# RL7005_IP_SVD register map
Vendor: Realtek
Registers are 32-bit, read-write, reset 0x0 unless marked. A register's access mark holds for its fields unless they carry their own. Offsets are from the block's base; [hi:lo] are bit positions; {n}, {i} and the like mark numbered series; <NAME> marks a mode.

## PAGE5 (part 1 of 2)
Base 0x40000000
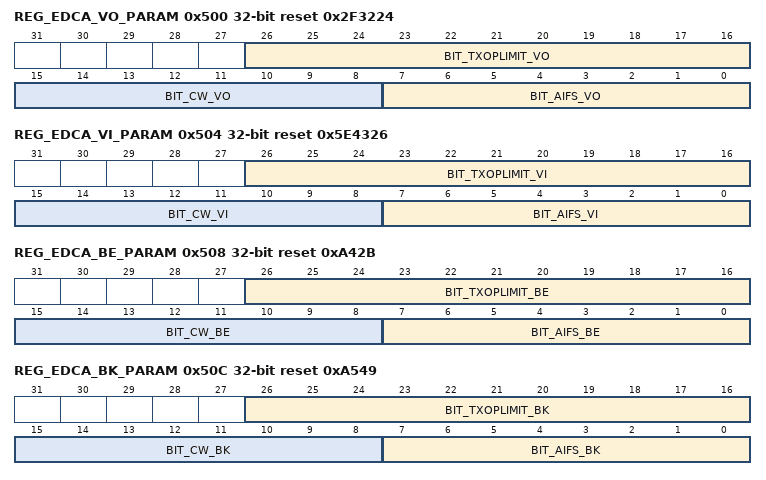
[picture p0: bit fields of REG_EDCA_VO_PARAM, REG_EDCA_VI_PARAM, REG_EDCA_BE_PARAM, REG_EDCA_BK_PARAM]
0x500 REG_EDCA_VO_PARAM reset 0x2F3224
  [26:16] BIT_TXOPLIMIT_VO — TXOP Limit An unsigned integer in units of 32 microseconds. Value of zero indicates that a single MSDU or MMPDU in addition to a protection frame exchange can be transmitted at any rate. Default: BK = 0h; BE = 0h; VI = 5Eh; VO = 2Fh.
  [15:8] BIT_CW_VO — ECWmin and ECWmax encode the values of Cwmin and Cwmax respectively in an exponent form. Ex: Cwmax = 2^(ECWmax)-1 Default: BK = Ah/5h; BE = Ah/5h; VI = 5h/4h; VO = 4h/3h.
  [7:0] BIT_AIFS_VO — Arbitrary Inter frame space In unit of microsecond. AIFS indicates the time a non-AP QSTA should defer before either invoking a backoff or starting a transmission Default: BK = 49h; BE = 25h; VI = 1Ch; VO = 1Ch.
0x504 REG_EDCA_VI_PARAM reset 0x5E4326
  [26:16] BIT_TXOPLIMIT_VI — TXOP Limit An unsigned integer in units of 32 microseconds. Value of zero indicates that a single MSDU or MMPDU in addition to a protection frame exchange can be transmitted at any rate. Default: BK = 0h; BE = 0h; VI = 5Eh; VO = 2Fh.
  [15:8] BIT_CW_VI — ECWmin and ECWmax encode the values of Cwmin and Cwmax respectively in an exponent form. Ex: Cwmax = 2^(ECWmax)-1 Default: BK = Ah/5h; BE = Ah/5h; VI = 5h/4h; VO = 4h/3h.
  [7:0] BIT_AIFS_VI — Arbitrary Inter frame space In unit of microsecond. AIFS indicates the time a non-AP QSTA should defer before either invoking a backoff or starting a transmission Default: BK = 49h; BE = 25h; VI = 1Ch; VO = 1Ch.
0x508 REG_EDCA_BE_PARAM reset 0xA42B
  [26:16] BIT_TXOPLIMIT_BE — TXOP Limit An unsigned integer in units of 32 microseconds. Value of zero indicates that a single MSDU or MMPDU in addition to a protection frame exchange can be transmitted at any rate. Default: BK = 0h; BE = 0h; VI = 5Eh; VO = 2Fh.
  [15:8] BIT_CW_BE — ECWmin and ECWmax encode the values of Cwmin and Cwmax respectively in an exponent form. Ex: Cwmax = 2^(ECWmax)-1 Default: BK = Ah/5h; BE = Ah/5h; VI = 5h/4h; VO = 4h/3h.
  [7:0] BIT_AIFS_BE — Arbitrary Inter frame space In unit of microsecond. AIFS indicates the time a non-AP QSTA should defer before either invoking a backoff or starting a transmission Default: BK = 49h; BE = 25h; VI = 1Ch; VO = 1Ch.
0x50C REG_EDCA_BK_PARAM reset 0xA549
  [26:16] BIT_TXOPLIMIT_BK — TXOP Limit An unsigned integer in units of 32 microseconds. Value of zero indicates that a single MSDU or MMPDU in addition to a protection frame exchange can be transmitted at any rate. Default: BK = 0h; BE = 0h; VI = 5Eh; VO = 2Fh.
  [15:8] BIT_CW_BK — ECWmin and ECWmax encode the values of Cwmin and Cwmax respectively in an exponent form. Ex: Cwmax = 2^(ECWmax)-1 Default: BK = Ah/5h; BE = Ah/5h; VI = 5h/4h; VO = 4h/3h.
  [7:0] BIT_AIFS_BK — Arbitrary Inter frame space In unit of microsecond. AIFS indicates the time a non-AP QSTA should defer before either invoking a backoff or starting a transmission Default: BK = 49h; BE = 25h; VI = 1Ch; VO = 1Ch.
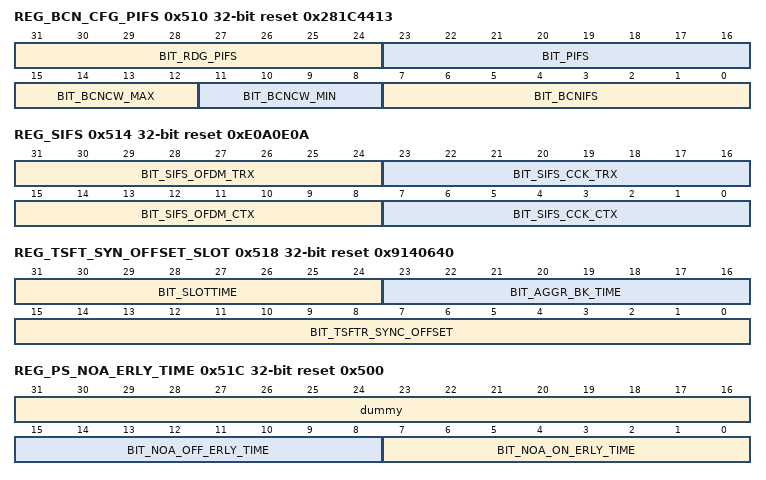
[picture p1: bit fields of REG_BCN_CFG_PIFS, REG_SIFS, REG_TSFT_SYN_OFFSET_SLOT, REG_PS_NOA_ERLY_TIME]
0x510 REG_BCN_CFG_PIFS reset 0x281C4413
  [31:24] BIT_RDG_PIFS — PIFS time. It is only used in RDG mode and in units of us.
  [23:16] BIT_PIFS — PIFS time. It is only used in AP mode and in units of us.
  [15:12] BIT_BCNCW_MAX — Beacon Contention Window MAX Defines the contention window value for back off before transmitting beacon frame. This field is set to 0 in AP mode to indicate no back off window. In ad hoc mode, its default value is 6. 26-1 = 63 time slots.
  [11:8] BIT_BCNCW_MIN — Beacon Contention Window Defines the contention window value for back off before transmitting beacon frame. This field is set to 0 in AP mode to indicate no back off window. In ad hoc mode, its default value is 6. 26-1 = 63 time slots.
  [7:0] BIT_BCNIFS — Beacon Interframe Space In units of microseconds, this register defines the medium idle time required before transmitting beacon (AP mode) or entering random back off window.
0x514 REG_SIFS reset 0xE0A0E0A
  [31:24] BIT_SIFS_OFDM_TRX — This register sets the SIFS time required in NAV protection period after receiving any immediate response. for example Ack-Data or RTS/CTS-Data. It is in unit of us.
  [23:16] BIT_SIFS_CCK_TRX — This register sets the SIFS time required in NAV protection period after receiving any immediate response. for example Ack-Data or RTS/CTS-Data. It is in unit of us.
  [15:8] BIT_SIFS_OFDM_CTX — This register sets the SIFS time required for consecutive TX events for example CTS2S-Data, or broadcast bursting. It is in unit of us.
  [7:0] BIT_SIFS_CCK_CTX — This register sets the SIFS time required for consecutive TX events for example CTS2S-Data, or broadcast bursting. It is in unit of us.
0x518 REG_TSFT_SYN_OFFSET_SLOT reset 0x9140640
  [31:24] BIT_SLOTTIME — This register sets the slot time value mentioned in 802.11 specification. It is in units of us. Default: 0x9
  [23:16] BIT_AGGR_BK_TIME — Hw will break aggr. In sifs condition
  [15:0] BIT_TSFTR_SYNC_OFFSET — tsft sync. Offset (bcn0 sync to bcn1 offset or bcn1 sync to bcn0 offset). Unit : 32us, default is 50ms
0x51C REG_PS_NOA_ERLY_TIME reset 0x500
  [31:16] dummy
  [15:8] BIT_NOA_OFF_ERLY_TIME — NOA off early interval, Time unit is TU.
  [7:0] BIT_NOA_ON_ERLY_TIME — not valid. NOA on early interval, Time unit is TU. PS: This function has some issue, so it's value must be 0
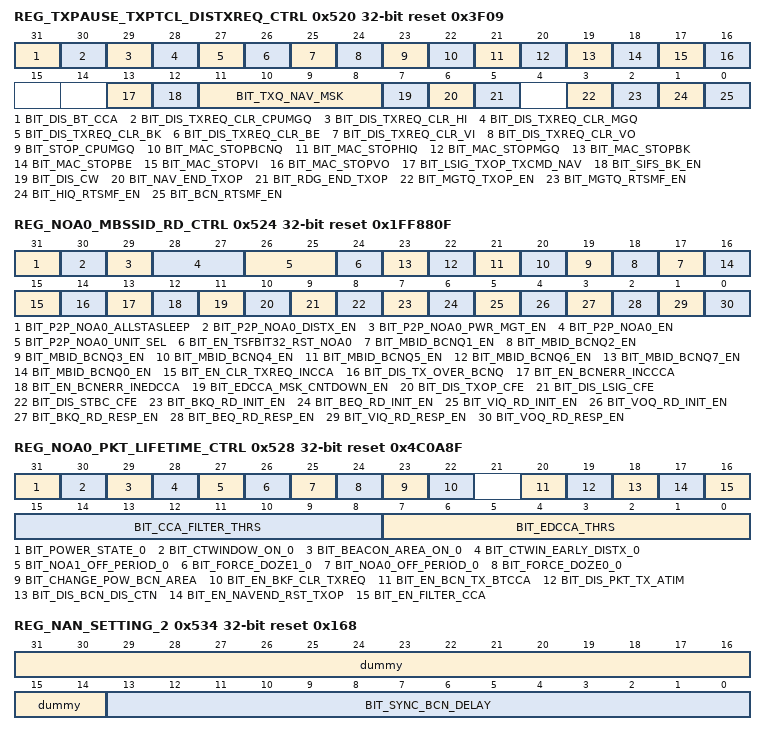
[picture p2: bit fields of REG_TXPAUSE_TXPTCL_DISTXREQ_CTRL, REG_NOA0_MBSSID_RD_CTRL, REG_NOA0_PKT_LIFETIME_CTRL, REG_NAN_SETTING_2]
0x520 REG_TXPAUSE_TXPTCL_DISTXREQ_CTRL reset 0x3F09
  [31] BIT_DIS_BT_CCA — Disable BT_CCA. (NOT USED, SEE 0x1594)
  [30] BIT_DIS_TXREQ_CLR_CPUMGQ — 1: if this queue can't own channel ,txcmd will be cleared 0:Only TX_finish can clear txreq
  [29] BIT_DIS_TXREQ_CLR_HI — 0: if this queue can't own channel ,txcmd will be cleared 1:Only TX_finish can clear txreq
  [28] BIT_DIS_TXREQ_CLR_MGQ — 1: if this queue can't own channel ,txcmd will be cleared 0:Only TX_finish can clear txreq
  [27] BIT_DIS_TXREQ_CLR_BK — 0: if this queue can't own channel ,txcmd will be cleared 1:Only TX_finish can clear txreq
  [26] BIT_DIS_TXREQ_CLR_BE — 0: if this queue can't own channel ,txcmd will be cleared 1:Only TX_finish can clear txreq
  [25] BIT_DIS_TXREQ_CLR_VI — 0: if this queue can't own channel ,txcmd will be cleared 1:Only TX_finish can clear txreq
  [24] BIT_DIS_TXREQ_CLR_VO — 0: if this queue can't own channel ,txcmd will be cleared 1:Only TX_finish can clear txreq
  [23] BIT_STOP_CPUMGQ — To control CPUMGQ queues contention circuit. 1: CPUMGQ queues all stop. 0: Enable CPUMGQ queues contention circuit
  [22] BIT_MAC_STOPBCNQ — Stop BCNQ Queue Write a 1 to this bit via software to immediately stop the transmission of packet from this queue including retry attempts.
  [21] BIT_MAC_STOPHIQ — Stop High Queue Write a 1 to this bit via software to immediately stop the transmission of packet from this queue including retry attempts.
  [20] BIT_MAC_STOPMGQ — Stop Management Queue Write a 1 to this bit via software to immediately stop the transmission of packet from this queue including retry attempts.
  [19] BIT_MAC_STOPBK — Stop BK Queue Write a 1 to this bit via software to immediately stop the transmission of packet from this queue including retry attempts.
  [18] BIT_MAC_STOPBE — Stop BE Queue Write a 1 to this bit via software to immediately stop the transmission of packet from this queue including retry attempts.
  [17] BIT_MAC_STOPVI — Stop VI Queue Write a 1 to this bit via software to immediately stop the transmission of packet from this queue including retry attempts.
  [16] BIT_MAC_STOPVO — Stop VO Queue Write a 1 to this bit via software to immediately stop the transmission of packet from this queue including retry attempts.
  [13] BIT_LSIG_TXOP_TXCMD_NAV — Set LSIG_TXOP from TXCMD_NAV field
  [12] BIT_SIFS_BK_EN — SIFS Break Check Criteria enable for AMPDU aggregation
  [11:8] BIT_TXQ_NAV_MSK — 1: Queue BKF must wait TX Nav finished 0: Queue not need wait
  [7] BIT_DIS_CW — When this bit is set, disable CW.
  [6] BIT_NAV_END_TXOP — 1: In txop mode, Nav protect all txop 0: In txop mode, Nav protect to next pkt
  [5] BIT_RDG_END_TXOP — 1: In tx RDG mode, Nav protect all txop 0: In tx RDG mode, Nav protect to next pkt
  [3] BIT_MGTQ_TXOP_EN — When this bit is set, MGTQ may sent packets by using ACQ TXOP.
  [2] BIT_MGTQ_RTSMF_EN — When this bit is set, MTGQ will be TX, not wait until RTS or MF transaction finished.
  [1] BIT_HIQ_RTSMF_EN — When this bit is set, HIQ will be TX, not wait until RTS or MF transaction finished.
  [0] BIT_BCN_RTSMF_EN — When this bit is set, BCNQ will be TX, not wait until RTS or MF transaction finished.
0x524 REG_NOA0_MBSSID_RD_CTRL reset 0x1FF880F
  [31] BIT_P2P_NOA0_ALLSTASLEEP — It indicates that the state from CTWindow End to BcnEarly 1: Sleep 0: Wake
  [30] BIT_P2P_NOA0_DISTX_EN — 1: Hw will disable TX in P2P_off period 0: Do Nothing
  [29] BIT_P2P_NOA0_PWR_MGT_EN — A main switch for P2P PowerSaving 1: Enable 0: Disable
  [28:27] BIT_P2P_NOA0_EN — The condition that noa_unit0, [1]-NOA1, [0]-NOA0 1: Enable 0: Disable
  [26:25] BIT_P2P_NOA0_UNIT_SEL — The selector for the source of noa unit0. 0 for port 0, 1 for port 1,2 for port2
  [24] BIT_EN_TSFBIT32_RST_NOA0 — when enable, if tsft_bit32_int is asserted, reset power_cs of noa_unit0
  [n+16] BIT_MBID_BCNQ{n}_EN (n=1..7) — When enable, auto MBSSID for virtual interface {n} is enable.
  [16] BIT_MBID_BCNQ0_EN — When enable, auto MBSSID for root interface is enable.
  [15] BIT_EN_CLR_TXREQ_INCCA — not valid.
  [14] BIT_DIS_TX_OVER_BCNQ — 1: Tx Packet with ignoring Beacon Area time 0: Disable
  [13] BIT_EN_BCNERR_INCCCA — eneble force tx becon ignore CCA in disable contention area
  [12] BIT_EN_BCNERR_INEDCCA — eneble force tx becon ignore EDCCA in disable contention area
  [11] BIT_EDCCA_MSK_CNTDOWN_EN — 1: disable EDCCA count down, 0: enable EDCCA count down AC backoff 是否需要參考PHY_EDCCA 0: 不參考PHY_EDCCA 1: 參考PHY_EDCCA (default, PHY_EDCCA=1時停止backoff)
  [10] BIT_DIS_TXOP_CFE — Disable TXOP_CFE function
  [9] BIT_DIS_LSIG_CFE — Disable LSIG_TXOP CF-END function
  [8] BIT_DIS_STBC_CFE — Disable STBC CF-END function
  [7] BIT_BKQ_RD_INIT_EN — Enable BKQ RD initiator function
  [6] BIT_BEQ_RD_INIT_EN — Enable BEQ RD initiator function
  [5] BIT_VIQ_RD_INIT_EN — Enable VIQ RD initiator function
  [4] BIT_VOQ_RD_INIT_EN — Enable VOQ RD initiator function
  [3] BIT_BKQ_RD_RESP_EN — Enable BKQ RD responder function
  [2] BIT_BEQ_RD_RESP_EN — Enable BEQ RD responder function
  [1] BIT_VIQ_RD_RESP_EN — Enable VIQ RD responder function
  [0] BIT_VOQ_RD_RESP_EN — Enable VOQ RD responder function
0x528 REG_NOA0_PKT_LIFETIME_CTRL access per field reset 0x4C0A8F
  [31] BIT_POWER_STATE_0 ro — 1: On, 0: Off. (It is including early time. )
  [30] BIT_CTWINDOW_ON_0 ro — Spec time and Beacon Early Time to TBTT Time. (It is including early time. )
  [29] BIT_BEACON_AREA_ON_0 ro — The time is from HOLD Time to BeaconTx or Timeout. (It is including early time. )
  [28] BIT_CTWIN_EARLY_DISTX_0 ro — ctwin_early_distx. (It is including early time. )
  [27] BIT_NOA1_OFF_PERIOD_0 ro — Spec time but exclude BCNDMATIM time for wake. (It is including early time. )
  [26] BIT_FORCE_DOZE1_0 ro — If NoA_Count == 1, this value is 1. else 0. (It is including early time. )
  [25] BIT_NOA0_OFF_PERIOD_0 ro — Spec time but exclude BCNDMATIM time for wake. (It is including early time. )
  [24] BIT_FORCE_DOZE0_0 ro — If NoA_Count == 1, this value is 1. else 0. (It is including early time. )
  [23] BIT_CHANGE_POW_BCN_AREA rw — select real_ctwindow & real_bcnq_area for noa_unit
  [22] BIT_EN_BKF_CLR_TXREQ rw — when gen tx command done, while will backoff is invalid, then tx command will be cleared
  [20] BIT_EN_BCN_TX_BTCCA rw — 1: Enable Beacon Tx at TBTT if BT_CCA is enabled 0: Disable
  [19] BIT_DIS_PKT_TX_ATIM rw — 1: Disable AC Queue Packet Tx in ATIM (only valid at Nettype: Adhoc/AP) 0: Enable AC Queue packet Tx in ATIM
  [18] BIT_DIS_BCN_DIS_CTN rw — Disable the Beacon queue disable contention,when set to 0 enable the force beacon function.
  [17] BIT_EN_NAVEND_RST_TXOP rw — When set this bit, TXOP will be reset while NAV end.
  [16] BIT_EN_FILTER_CCA rw — Enable CCA filter threshold
  [15:8] BIT_CCA_FILTER_THRS rw — If PHY_CCA signal width is bigger than this threshold, this PHY_CCA signal is valid for MAC. Unit: us
  [7:0] BIT_EDCCA_THRS rw — EDCCA threshold value, edcca over this threshold will cause bkf_rst Bit[7]: PHY_EDCCA為1時,當timer timeout時擋住TX Bit[6:0]: timer (單位:32us)
0x530 REG_P2PON_DIS_TXTIME
  [15:8] BIT_P2PON_DIS_TXTIME — The time of the disable TX period after the P2P RF on interrupt occur. Unit: 64us.
0x534 REG_NAN_SETTING_2 reset 0x168
  [31:14] dummy
  [13:0] BIT_SYNC_BCN_DELAY — r_HC * r_SLOTTIME * 8'd40 (unit:us) default: r_HC = 1, r_SLOTTIME = 9, => 360us max is 16ms (DW)
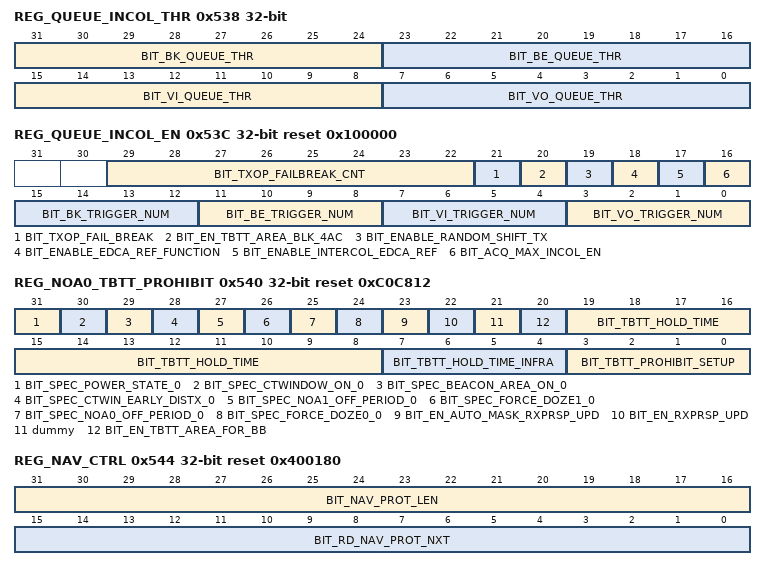
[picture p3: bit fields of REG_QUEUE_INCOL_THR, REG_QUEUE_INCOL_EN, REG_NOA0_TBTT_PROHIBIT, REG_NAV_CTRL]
0x538 REG_QUEUE_INCOL_THR
  [31:24] BIT_BK_QUEUE_THR — 0: Disable this BK queue condition. Otherwise: When internal collision number of queue equal threshold, the priority of queue enhance. But have more 2 queues which satisfy each queue threshold, the priority will follow VO>VI>BE>BK.
  [23:16] BIT_BE_QUEUE_THR — 0: Disable this BE queue condition. Otherwise: When internal collision number of queue equal threshold, the priority of queue enhance. But have more 2 queues which satisfy each queue threshold, the priority will follow VO>VI>BE>BK.
  [15:8] BIT_VI_QUEUE_THR — 0: Disable this VI queue condition. Otherwise: When internal collision number of queue equal threshold, the priority of queue enhance. But have more 2 queues which satisfy each queue threshold, the priority will follow VO>VI>BE>BK.
  [7:0] BIT_VO_QUEUE_THR — 0: Disable this VO queue condition. Otherwise: When internal collision number of queue equal threshold, the priority of queue enhance. But have more 2 queues which satisfy each queue threshold, the priority will follow VO>VI>BE>BK.
0x53C REG_QUEUE_INCOL_EN access per field reset 0x100000
  [29:22] BIT_TXOP_FAILBREAK_CNT ro — if BIT_TXOP_FAIL_BREAK = 1, counter the times of txfail break TXOP
  [21] BIT_TXOP_FAIL_BREAK rw — 1: if tx pkt fail in txop, then tx cfend to end txop
  [20] BIT_EN_TBTT_AREA_BLK_4AC rw — When set this bit, 4AC backoff is disabled on TBTT setup period
  [19] BIT_ENABLE_RANDOM_SHIFT_TX rw — When this bit set 1, enable random shift TX function
  [18] BIT_ENABLE_EDCA_REF_FUNCTION rw — When this bit set 1, enable EDCA REF function
  [17] BIT_ENABLE_INTERCOL_EDCA_REF rw — When this bit set 1, enable inter-collision edca_ref
  [16] BIT_ACQ_MAX_INCOL_EN rw — 1:Enable 0 :Disable
  [15:12] BIT_BK_TRIGGER_NUM ro — The number is triggered by bkq inter collision
  [11:8] BIT_BE_TRIGGER_NUM ro — The number is triggered by beq inter collision
  [7:4] BIT_VI_TRIGGER_NUM ro — The number is triggered by viq inter collision
  [3:0] BIT_VO_TRIGGER_NUM ro — The number is triggered by voq inter collision
0x540 REG_NOA0_TBTT_PROHIBIT access per field reset 0xC0C812
  [31] BIT_SPEC_POWER_STATE_0 ro — 1: On, 0: Off
  [30] BIT_SPEC_CTWINDOW_ON_0 ro — The time from TBTT <-> CTWEND (with BCNDMATIM early time)
  [29] BIT_SPEC_BEACON_AREA_ON_0 ro — The time is from TBTT to BeaconTx or Timeout
  [28] BIT_SPEC_CTWIN_EARLY_DISTX_0 ro — ctwin_early_distx
  [27] BIT_SPEC_NOA1_OFF_PERIOD_0 ro — Spec time
  [26] BIT_SPEC_FORCE_DOZE1_0 ro — If NoA_Count == 1, this value is 1. else 0.
  [25] BIT_SPEC_NOA0_OFF_PERIOD_0 ro — Spec time
  [24] BIT_SPEC_FORCE_DOZE0_0 ro — If NoA_Count == 1, this value is 1. else 0.
  [23] BIT_EN_AUTO_MASK_RXPRSP_UPD rw — valid when BIT_EN_RXPRSP_UPD = 1 1: auto disable RXPRSP's tsft update when rx probe response frame during bcn_early to tbtt
  [22] BIT_EN_RXPRSP_UPD rw — 1: enable update tsft when RX probe response frame
  [21] dummy rw
  [20] BIT_EN_TBTT_AREA_FOR_BB rw — enable notify bb that mac p0 is in tbtt area
  [19:8] BIT_TBTT_HOLD_TIME rw — TBTT_prohibit_hold time for AP mode, unit is 32 us
  [7:4] BIT_TBTT_HOLD_TIME_INFRA rw — TBTT_prohibit_hold time for infrastructure mode , unit is 2 ms
  [3:0] BIT_TBTT_PROHIBIT_SETUP rw — TBTT_prohibit_setup, unit is 32us
0x544 REG_NAV_CTRL reset 0x400180
  [31:16] BIT_NAV_PROT_LEN — In TXOP mode ,NAV setting which protects next packets
  [15:0] BIT_RD_NAV_PROT_NXT — In RDG mode ,NAV setting which protects next packets
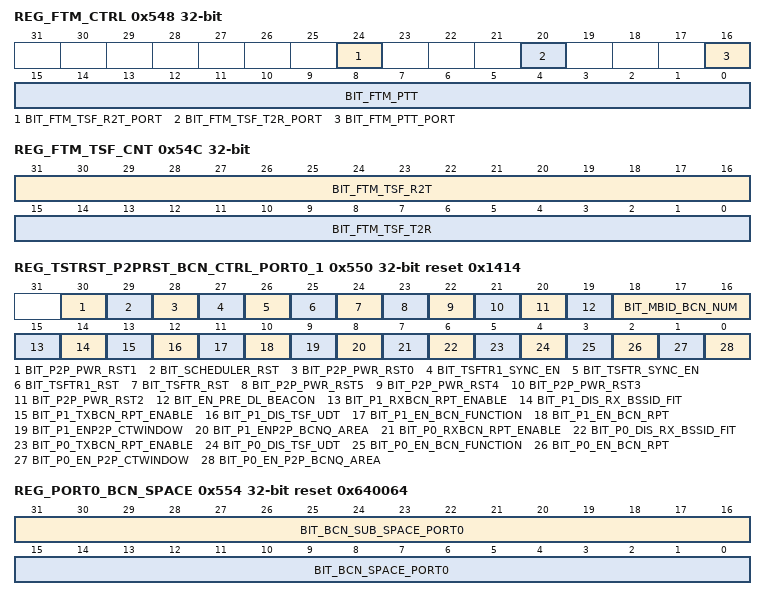
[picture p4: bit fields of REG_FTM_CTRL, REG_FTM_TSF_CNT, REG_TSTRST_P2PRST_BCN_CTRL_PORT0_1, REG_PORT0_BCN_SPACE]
0x548 REG_FTM_CTRL
  [24] BIT_FTM_TSF_R2T_PORT — 0:R2T latch count sync tsf of port 0 1: R2T latch count sync tsf of port 1
  [20] BIT_FTM_TSF_T2R_PORT — 0:T2R latch count sync tsf of port 0 1: T2R latch count sync tsf of port 1
  [16] BIT_FTM_PTT_PORT — 0: sync tsf of port 0 1: sync tsf of port 1
  [15:0] BIT_FTM_PTT — partial tsf timer setting
0x54C REG_FTM_TSF_CNT ro
  [31:16] BIT_FTM_TSF_R2T — R2T latch count sync tsf timer
  [15:0] BIT_FTM_TSF_T2R — T2R latch count sync tsf timer
0x550 REG_TSTRST_P2PRST_BCN_CTRL_PORT0_1 access per field reset 0x1414
  [30] BIT_P2P_PWR_RST1 wo — rst p2p circuit NOA 1, noa_unit0
  [29] BIT_SCHEDULER_RST wo — Write this bit reset scheduler, ioreg_txfail
  [28] BIT_P2P_PWR_RST0 wo — rst p2p circuit NOA 0, noa_unit0
  [27] BIT_TSFTR1_SYNC_EN wo — write this bit, bcn1 will sync to bcn0 with TSFTF_SYN_OFFSET
  [26] BIT_TSFTR_SYNC_EN wo — write this bit, bcn0 will sync to bcn1 with TSFTF_SYN_OFFSET
  [25] BIT_TSFTR1_RST wo — write this bit , bcn1 tsft will auto reset
  [24] BIT_TSFTR_RST wo — write this bit , bcn0 tsft will auto reset
  [23] BIT_P2P_PWR_RST5 wo — rst p2p circuit NOA 5, noa_unit2
  [22] BIT_P2P_PWR_RST4 wo — rst p2p circuit NOA 4, noa_unit2
  [21] BIT_P2P_PWR_RST3 wo — rst p2p circuit NOA 3, noa_unit1
  [20] BIT_P2P_PWR_RST2 wo — rst p2p circuit NOA 2, noa_unit1
  [19] BIT_EN_PRE_DL_BEACON rw — If set 1, hw will enable pre_download beacon
  [18:16] BIT_MBID_BCN_NUM rw — The number of virtual interface number excluding the root number.
  [15] BIT_P1_RXBCN_RPT_ENABLE rw — When this bit asserted, RXBCNOK report is issued
  [14] BIT_P1_DIS_RX_BSSID_FIT rw — 0:HW will handle rx_beacon 1:HW will ignore rx_beacon_pk
  [13] BIT_P1_TXBCN_RPT_ENABLE rw — When this bit and BIT_P1_EN_BCN_RPT are set, then TXBCN ERROR report is issued
  [12] BIT_P1_DIS_TSF_UDT rw — When set, disable clint 0 TSF update when beacon frames or probe response frames are received.
  [11] BIT_P1_EN_BCN_FUNCTION rw — When this bit is set, TSF and other beacon related functions are then enabled. 0x700(MACID1)的enable開關
  [10] BIT_P1_EN_BCN_RPT rw — When this bit asserted, txbcnok_int and txbcnerr_int will valid.
  [9] BIT_P1_ENP2P_CTWINDOW rw — 1: Enable P2P CTN WINDOWS function. 0: Disable P2P CTN WINDOWS function.
  [8] BIT_P1_ENP2P_BCNQ_AREA rw — 1: Enable P2P BCN area on function. 0 : Disable P2P BCN area on function.
  [7] BIT_P0_RXBCN_RPT_ENABLE rw — When this bit asserted, RXBCNOK report is issued
  [6] BIT_P0_DIS_RX_BSSID_FIT rw — 0:HW will handle rx_beacon 1:HW will ignore rx_beacon_pk
  [5] BIT_P0_TXBCN_RPT_ENABLE rw — When this bit and BIT_P0_EN_BCN_RPT are set, then TXBCN ERROR report is issued
  [4] BIT_P0_DIS_TSF_UDT rw — When set, disable port 0 TSF update when beacon frames or probe response frames are received.
  [3] BIT_P0_EN_BCN_FUNCTION rw — When this bit is set, TSF and other beacon related functions are then enabled. 0x610(MACID)的enable開關
  [2] BIT_P0_EN_BCN_RPT rw — When this bit asserted, txbcnok_int and txbcnerr_int will valid.
  [1] BIT_P0_EN_P2P_CTWINDOW rw — 1: Enable P2P CTN WINDOWS function. 0: Disable P2P CTN WINDOWS function.
  [0] BIT_P0_EN_P2P_BCNQ_AREA rw — 1: Enable P2P BCN area on function. 0 : Disable P2P BCN area on function.
0x554 REG_PORT0_BCN_SPACE reset 0x640064
  [31:16] BIT_BCN_SUB_SPACE_PORT0 — Unit is ms. The sub-beacon interval of the port 0.(valid if mbssid function is enable)
  [15:0] BIT_BCN_SPACE_PORT0 — Unit is ms. When MBSSID is disable, this field is the beacon interval. When MBSSID is enable, this register is the beacon space of root.
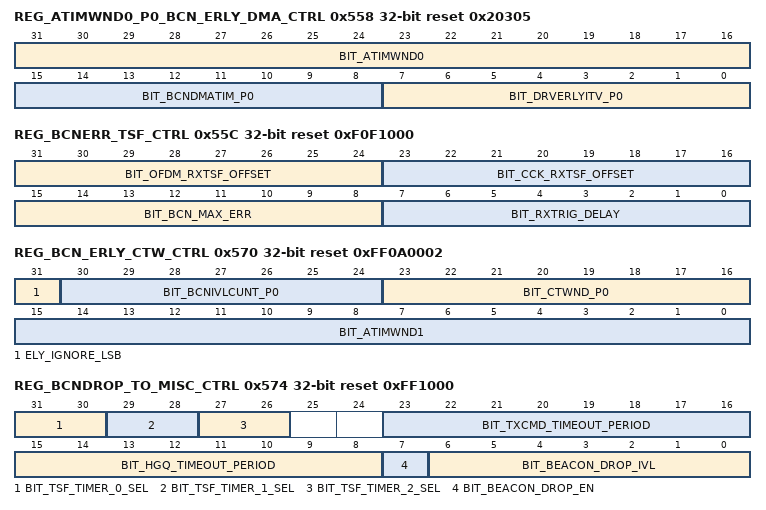
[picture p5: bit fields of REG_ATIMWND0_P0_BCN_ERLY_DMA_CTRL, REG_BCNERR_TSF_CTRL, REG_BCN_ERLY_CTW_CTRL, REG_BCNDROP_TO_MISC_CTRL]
0x558 REG_ATIMWND0_P0_BCN_ERLY_DMA_CTRL reset 0x20305
  [31:16] BIT_ATIMWND0 — ATIM window width of root VAP in units of TU.
  [15:8] BIT_BCNDMATIM_P0 — Indicates the time before TBTT to perform beacon queue DMA. This register is shared by the time to assert ATIM window end interrupt. Measured in units of "TU" before TBTT and before ATIM window end.
  [7:0] BIT_DRVERLYITV_P0 — Time to send interrupt to notify driver to change beacon content. Time unit is TU. The register also is shared by P2P-CTW and P2P-NoA (from NoA-Absent to NoA-On). It is used to wake up early at DriverEarlyTime
0x55C REG_BCNERR_TSF_CTRL reset 0xF0F1000
  [31:24] BIT_OFDM_RXTSF_OFFSET — The Datapath of OFDM RX_tsf
  [23:16] BIT_CCK_RXTSF_OFFSET — The Datapath of CCK RX_tsf
  [15:8] BIT_BCN_MAX_ERR — When beacon TX error counter goes over this threshold, Beacon will transmit within PIFS.
  [7:0] BIT_RXTRIG_DELAY — add compensation of RX trigger's TSFT. Unit: us
0x560 REG_P0_TSFTR_L reset 0x1
  [31:0] BIT_P0_TSF_TIMER_L — low 32bits of port0's tsft
0x564 REG_P0_TSFTR_H
  [31:0] BIT_P0_TSF_TIMER_H — high 32bits of port0's tsft
0x568 REG_P1_TSFTR_L reset 0x1
  [31:0] BIT_P1_TSF_TIMER_L — low 32bits of port1's tsft
0x56C REG_P1_TSFTR_H reset 0x1
  [31:0] BIT_P1_TSF_TIMER_H — high 32bits of port1's tsft
0x570 REG_BCN_ERLY_CTW_CTRL access per field reset 0xFF0A0002
  [31] ELY_IGNORE_LSB rw — 1:add1ms, add128us, add32us only check tsft[10], tsft[7], tsft[5], ignore LSB 0: add1ms, add128us, add32us check tsft[9:0], tsft[6:0], tsft[4:0] when active
  [30:24] BIT_BCNIVLCUNT_P0 ro — Be used in multiple BCNIVL early INT. When this counter =1, multiple BCNIVL early INT will be triggered.
  [23:16] BIT_CTWND_P0 rw — CTWindow width in units of TU. PORT0
  [15:0] BIT_ATIMWND1 rw — ATIM window width of VAP1 in units of TU.
0x574 REG_BCNDROP_TO_MISC_CTRL reset 0xFF1000
  [31:30] BIT_TSF_TIMER_0_SEL — genarete tsfime_int[0] 00: PORT0's tsft 01: PORT1's tsft 10:PORT2's tsft 11: FREERUN CUT
  [29:28] BIT_TSF_TIMER_1_SEL — genarete tsfime_int[1] 00: PORT0's tsft 01: PORT1's tsft 10:PORT2's tsft 11: FREERUN CUT
  [27:26] BIT_TSF_TIMER_2_SEL — genarete tsfime_int[2] 00: PORT0's tsft 01: PORT1's tsft 10:PORT2's tsft 11: FREERUN CUT
  [23:16] BIT_TXCMD_TIMEOUT_PERIOD — When 40M/80M TX CMD ready and secondary_CCA_20/secondary_CCA_40 set for this period, then the TX CMD will be cleared. TU: 1us
  [15:8] BIT_HGQ_TIMEOUT_PERIOD — When hgq empty for this period, close atim window. And this will block hgq dma for pcie, unless 0x524[12] set enable. TU: 32us
  [7] BIT_BEACON_DROP_EN — enable beacon drop function
  [6:0] BIT_BEACON_DROP_IVL — indicate the timeout of beacon drop
0x578 REG_P2_TSFTR_L ro reset 0x1
  [31:0] BIT_P2_TSF_TIMER_L — low 32bits of port2's tsft (NAN)
0x57C REG_P2_TSFTR_H ro reset 0x1
  [31:0] BIT_P2_TSF_TIMER_H — high 32bits of port2's tsft(NAN)
{0x57C+4i} REG_TSF_TIMER{i} (i=1..3)
  [31:5] BIT_TSTTIMER{i} — When the lower 4 bytes of TSFTR matches the content of this register, the FW tsftime_int[{i-1}] interrupt is issued.
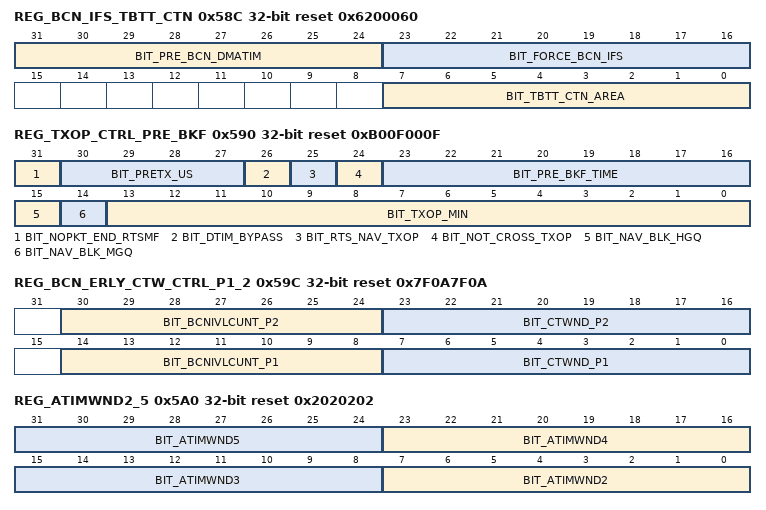
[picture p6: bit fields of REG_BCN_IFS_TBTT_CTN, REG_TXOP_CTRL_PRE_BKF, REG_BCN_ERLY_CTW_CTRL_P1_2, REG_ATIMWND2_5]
0x58C REG_BCN_IFS_TBTT_CTN reset 0x6200060
  [31:24] BIT_PRE_BCN_DMATIM — when 0x552[3] is set, hw will enable pre_download beacon. this register Indicates the time before TBTT to perform beacon queue DMA.
  [23:16] BIT_FORCE_BCN_IFS — when 0x528 Bit18 set to 0 and TBTT contention area end,force tx beacon use this IFS
  [7:0] BIT_TBTT_CTN_AREA — TBTT contention area,Time unit is 32us,for PORT 0 / 1 / 2
0x590 REG_TXOP_CTRL_PRE_BKF reset 0xB00F000F
  [31] BIT_NOPKT_END_RTSMF — 1: enable exit rts hold mode when there is no corresponding ac pkt to tx
  [30:27] BIT_PRETX_US — For wep/tkip, enable security engine earlier than mactx by this amount of time. Unit is microsecond (us)
  [26] BIT_DTIM_BYPASS — 1: dtim counter will keep 0
  [25] BIT_RTS_NAV_TXOP — enable RTS NAV protect all txop
  [24] BIT_NOT_CROSS_TXOP — 1:tx pkt cross tbtt is prohibited 0:tx pkt cross tbtt is permitted
  [23:16] BIT_PRE_BKF_TIME — when bkf timer count down this value, sel queue and gen txcmd will start
  [15] BIT_NAV_BLK_HGQ — rxnav block HGQ
  [14] BIT_NAV_BLK_MGQ — rxnav block MGQ
  [13:0] BIT_TXOP_MIN — if txop counter is more than this value, than tx pkt is considered not cross tbtt
0x594 REG_FREERUN_CNT_L reset 0x1
  [31:0] BIT_FREERUN_CNT_TIMER_L — LOW 32bits of freerun cnt
0x598 REG_FREERUN_CNT_H reset 0x1
  [31:0] BIT_FREERUN_CNT_TIMER_H — high 32bits of freerun cnt
0x59C REG_BCN_ERLY_CTW_CTRL_P1_2 access per field reset 0x7F0A7F0A
  [30:24] BIT_BCNIVLCUNT_P2 ro — Be used in multiple BCNIVL early INT. When this counter =1, multiple BCNIVL early INT will be triggered.
  [23:16] BIT_CTWND_P2 rw — CTWindow width in units of TU. PORT2
  [14:8] BIT_BCNIVLCUNT_P1 ro — Be used in multiple BCNIVL early INT. When this counter =1, multiple BCNIVL early INT will be triggered.
  [7:0] BIT_CTWND_P1 rw — CTWindow width in units of TU. PORT1
0x5A0 REG_ATIMWND2_5 reset 0x2020202
  [8n-9:8n-16] BIT_ATIMWND{n} (n=2..5) — ATIM window width of VAP{n} in units of TU.
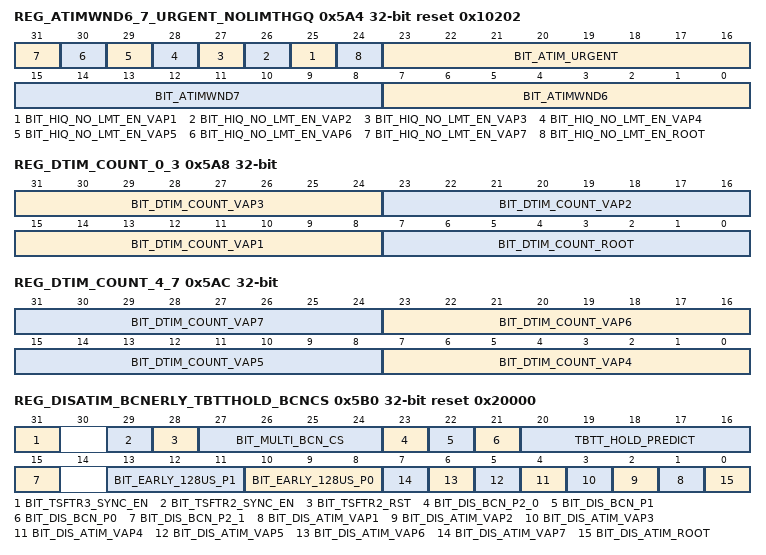
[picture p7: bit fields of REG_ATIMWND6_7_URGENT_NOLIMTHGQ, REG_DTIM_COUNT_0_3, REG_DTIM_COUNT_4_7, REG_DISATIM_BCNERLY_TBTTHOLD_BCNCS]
0x5A4 REG_ATIMWND6_7_URGENT_NOLIMTHGQ reset 0x10202
  [n+24] BIT_HIQ_NO_LMT_EN_VAP{n} (n=1..7) — 1: Packet in Hi Queue Tx immediately (No constraint for ATIM Period) 0: Disable
  [24] BIT_HIQ_NO_LMT_EN_ROOT — 1: Packet in Hi Queue Tx immediately (No constraint for ATIM Period) 0: Disable
  [23:16] BIT_ATIM_URGENT — Indicates the time before ATIM Window end . When BSSID[n] (n=0~7) has HIQ packet to send, HW only DMA BSSID[n]'s HIQ packet in this interval. (unit : TU)
  [15:8] BIT_ATIMWND7 — ATIM window width of VAP7 in units of TU.
  [7:0] BIT_ATIMWND6 — ATIM window width of VAP6 in units of TU.
0x5A8 REG_DTIM_COUNT_0_3
  [31:24] BIT_DTIM_COUNT_VAP3, [23:16] BIT_DTIM_COUNT_VAP2, [15:8] BIT_DTIM_COUNT_VAP1, [7:0] BIT_DTIM_COUNT_ROOT
0x5AC REG_DTIM_COUNT_4_7
  [8n-25:8n-32] BIT_DTIM_COUNT_VAP{n} (n=4..7)
0x5B0 REG_DISATIM_BCNERLY_TBTTHOLD_BCNCS access per field reset 0x20000
  [31] BIT_TSFTR3_SYNC_EN wo — write this bit, PORT3 will sync to PORT2 with TSFTF_SYN_OFFSET
  [29] BIT_TSFTR2_SYNC_EN wo — write this bit, PORT2 backup TSFT will sync to PORT2 TSFT without TSFTF_SYN_OFFSET
  [28] BIT_TSFTR2_RST wo — write this bit , bcn2 tsft will auto reset
  [27:24] BIT_MULTI_BCN_CS ro — indicate which port is tx beacon
  [23] BIT_DIS_BCN_P2_0 rw — set 1 to mask the NAN disc beacon early interrupt of port2
  [22] BIT_DIS_BCN_P1 rw — set 1 to mask the beacon early interrupt of port1
  [21] BIT_DIS_BCN_P0 rw — set 1 to mask the beacon early interrupt of port0
  [20:16] TBTT_HOLD_PREDICT rw — the predicted hold time after tbtt for P0 RX beacon, unit is 1ms
  [15] BIT_DIS_BCN_P2_1 rw — set 1 to mask the NAN sync beacon early interrupt of port2
  [13:11] BIT_EARLY_128US_P1 rw — the BCN EARLY interrupt find tune with unit 128us. The Total Early time of BCN early interrupt is the 0x558 x 1ms + EARLY_128us x 128us. For port 1
  [10:8] BIT_EARLY_128US_P0 rw — the BCN EARLY interrupt find tune with unit 128us. The Total Early time of BCN early interrupt is the 0x558 x 1ms + EARLY_128us x 128us.
  [n] BIT_DIS_ATIM_VAP{n} rw (n=1..7)
  [0] BIT_DIS_ATIM_ROOT rw
